# ETHSW register map
Registers are 32-bit, read-only, no defined reset value unless marked. A register's access mark holds for its fields unless they carry their own. Addresses are absolute; registers are grouped by the start of their names; [hi:lo] are bit positions; {n}, {i} and the like mark numbered series.

## LOC
0x44053C14 LOC_MAClo access not given
  [31:0] LOC_MAC
0x44053C18 LOC_MAChi access not given
  [15:0] LOC_MAC

## SUPR
0x44053C20 SUPR_MAClo
  [31:0] SUPR_MAC
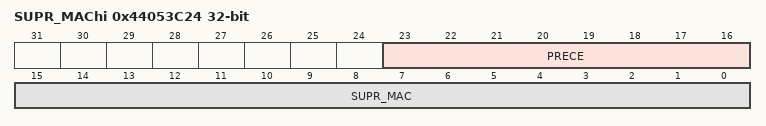
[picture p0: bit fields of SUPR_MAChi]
0x44053C24 SUPR_MAChi
  [23:16] PRECE, [15:0] SUPR_MAC
0x44053C34 SUPR_IPADR

## BEC
0x44053C2C BEC_TMOUT
0x44053C30 BEC_INTRVL

## RX
0x44053C60 RX_STAT0
0x44053C64 RX_ERR_STAT0
0x44053C70 RX_STAT1
0x44053C74 RX_ERR_STAT1

## PRP
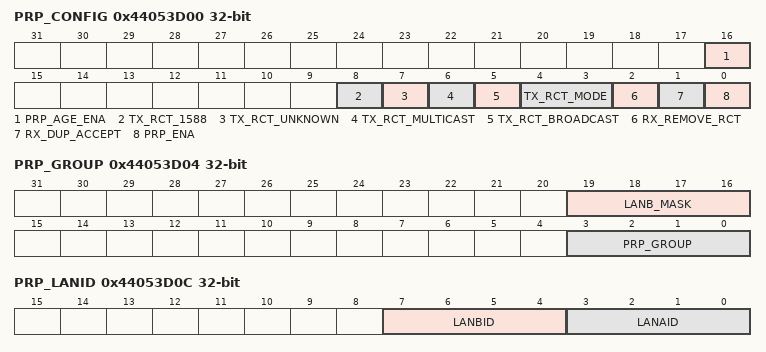
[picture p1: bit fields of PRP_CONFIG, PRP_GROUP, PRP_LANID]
0x44053D00 PRP_CONFIG access not given
  [16] PRP_AGE_ENA, [8] TX_RCT_1588, [7] TX_RCT_UNKNOWN, [6] TX_RCT_MULTICAST, [5] TX_RCT_BROADCAST, [4:3] TX_RCT_MODE, [2] RX_REMOVE_RCT, [1] RX_DUP_ACCEPT, [0] PRP_ENA
0x44053D04 PRP_GROUP access not given
  [19:16] LANB_MASK, [3:0] PRP_GROUP
0x44053D08 PRP_SUFFIX access not given
  [15:0] PRP_SUFFIX
0x44053D0C PRP_LANID access not given
  [7:4] LANBID, [3:0] LANAID
0x44053D14 PRP_AGETIME access not given
  [23:0] PRP_AGETIME
0x44053D1C PRP_IRQ_STAT_ACK access not given
  [3:0] see_IRQ_CONTROL_register_bits

## RM
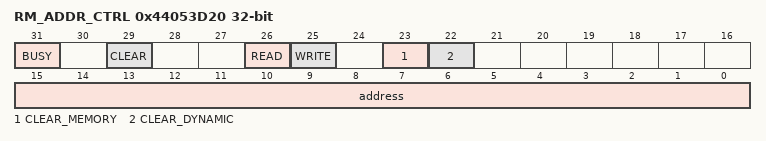
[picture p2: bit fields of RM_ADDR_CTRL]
0x44053D20 RM_ADDR_CTRL access not given
  [31] BUSY, [29] CLEAR, [26] READ, [25] WRITE, [23] CLEAR_MEMORY, [22] CLEAR_DYNAMIC, [15:0] address
0x44053D24 RM_DATA access not given
0x44053D2C RM_STATUS
  [15:0] ageaddress

## HUB
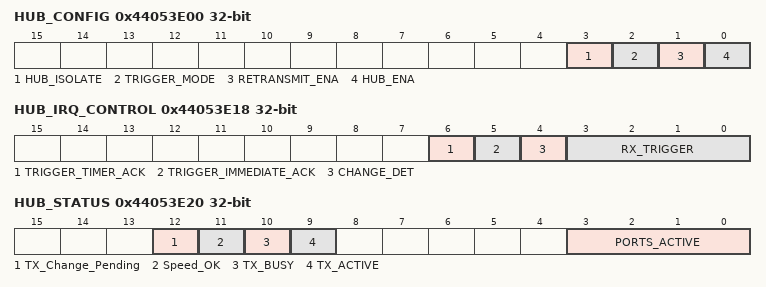
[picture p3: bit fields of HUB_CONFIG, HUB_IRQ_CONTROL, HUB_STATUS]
0x44053E00 HUB_CONFIG access not given
  [3] HUB_ISOLATE, [2] TRIGGER_MODE, [1] RETRANSMIT_ENA, [0] HUB_ENA
0x44053E04 HUB_GROUP access not given
  [3:0] HUB_GROUP
0x44053E08 HUB_DEFPORT access not given
  [3:0] HUB_DEFPORT
0x44053E0C HUB_TRIGGER_IMMEDIATE access not given
  [3:0] HUB_TRIGGER_IMMEDIATE
0x44053E10 HUB_TRIGGER_AT access not given
  [3:0] HUB_TRIGGER_AT
0x44053E14 HUB_TTIME access not given
0x44053E18 HUB_IRQ_CONTROL access not given
  [6] TRIGGER_TIMER_ACK, [5] TRIGGER_IMMEDIATE_ACK, [4] CHANGE_DET, [3:0] RX_TRIGGER
0x44053E1C HUB_IRQ_STAT_ACK access not given
  [6:0] INT_PEND
0x44053E20 HUB_STATUS
  [12] TX_Change_Pending, [11] Speed_OK, [10] TX_BUSY, [9] TX_ACTIVE, [3:0] PORTS_ACTIVE
0x44053E24 HUB_OPORT_STATUS
  [3:0] HUB_OPORT_STATUS

## RXMATCH
{0x44053E80+4i} RXMATCH_CONFIG{i} access not given (i=0..4)
  [7:0] PATTERN_EN

## PATTERN
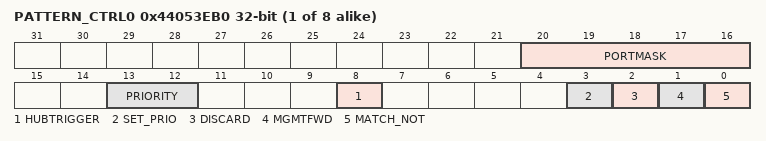
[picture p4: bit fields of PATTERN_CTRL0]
{0x44053EB0+4i} PATTERN_CTRL{i} access not given (i=0..7)
  [20:16] PORTMASK, [13:12] PRIORITY, [8] HUBTRIGGER, [3] SET_PRIO, [2] DISCARD, [1] MGMTFWD, [0] MATCH_NOT
0x44053EDC PATTERN_SEL access not given
  [2:0] PATTERN_SEL

## PTN
0x44053ED0 PTN_IRQ_CONTROL access not given
  [7:0] MATCHINT
0x44053ED4 PTN_IRQ_STAT_ACK access not given
  [7:0] MATCHINT

## PTRN
0x44053EE0 PTRN_CMP_30 access not given
0x44053EE4 PTRN_CMP_74 access not given
0x44053EE8 PTRN_CMP_118 access not given
0x44053EF0 PTRN_MSK_30 access not given
0x44053EF4 PTRN_MSK_74 access not given
0x44053EF8 PTRN_MSK_118 access not given

## TDMA
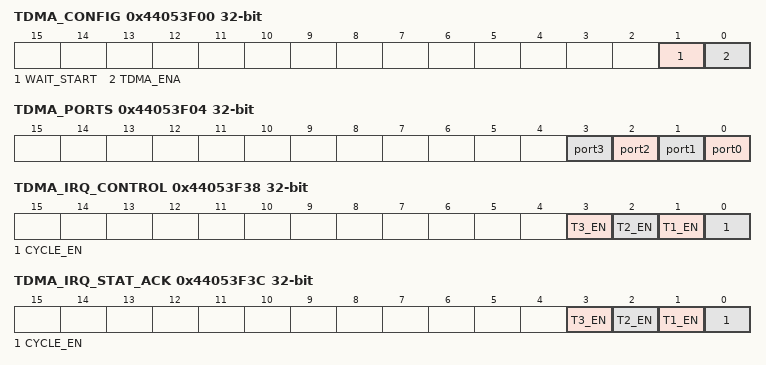
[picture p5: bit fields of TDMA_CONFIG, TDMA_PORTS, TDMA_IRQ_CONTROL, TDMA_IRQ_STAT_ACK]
0x44053F00 TDMA_CONFIG access not given
  [1] WAIT_START, [0] TDMA_ENA
0x44053F04 TDMA_PORTS access not given
  [n] port{n} (n=0..3)
0x44053F08 TDMA_START access not given
0x44053F0C TDMA_MODULO access not given
0x44053F10 TDMA_CYCLE access not given
{0x44053F10+4i} TDMA_T{i} access not given (i=1..3)
0x44053F38 TDMA_IRQ_CONTROL access not given
  [3] T3_EN, [2] T2_EN, [1] T1_EN, [0] CYCLE_EN
0x44053F3C TDMA_IRQ_STAT_ACK access not given
  [3] T3_EN, [2] T2_EN, [1] T1_EN, [0] CYCLE_EN

## QUEUES
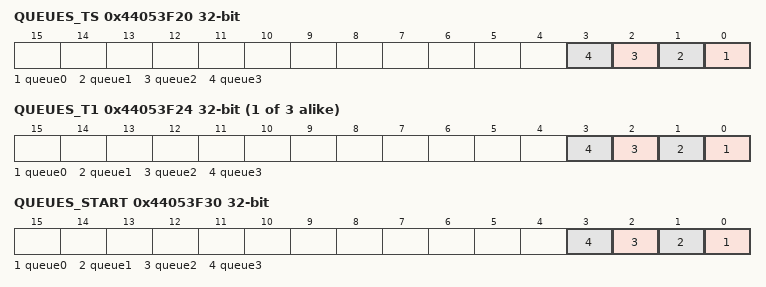
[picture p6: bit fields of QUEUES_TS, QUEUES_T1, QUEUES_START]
0x44053F20 QUEUES_TS access not given
  [n] queue{n} (n=0..3)
{0x44053F20+4i} QUEUES_T{i} access not given (i=1..3)
  [n] queue{n} (n=0..3)
0x44053F30 QUEUES_START access not given
  [n] queue{n} (n=0..3)
